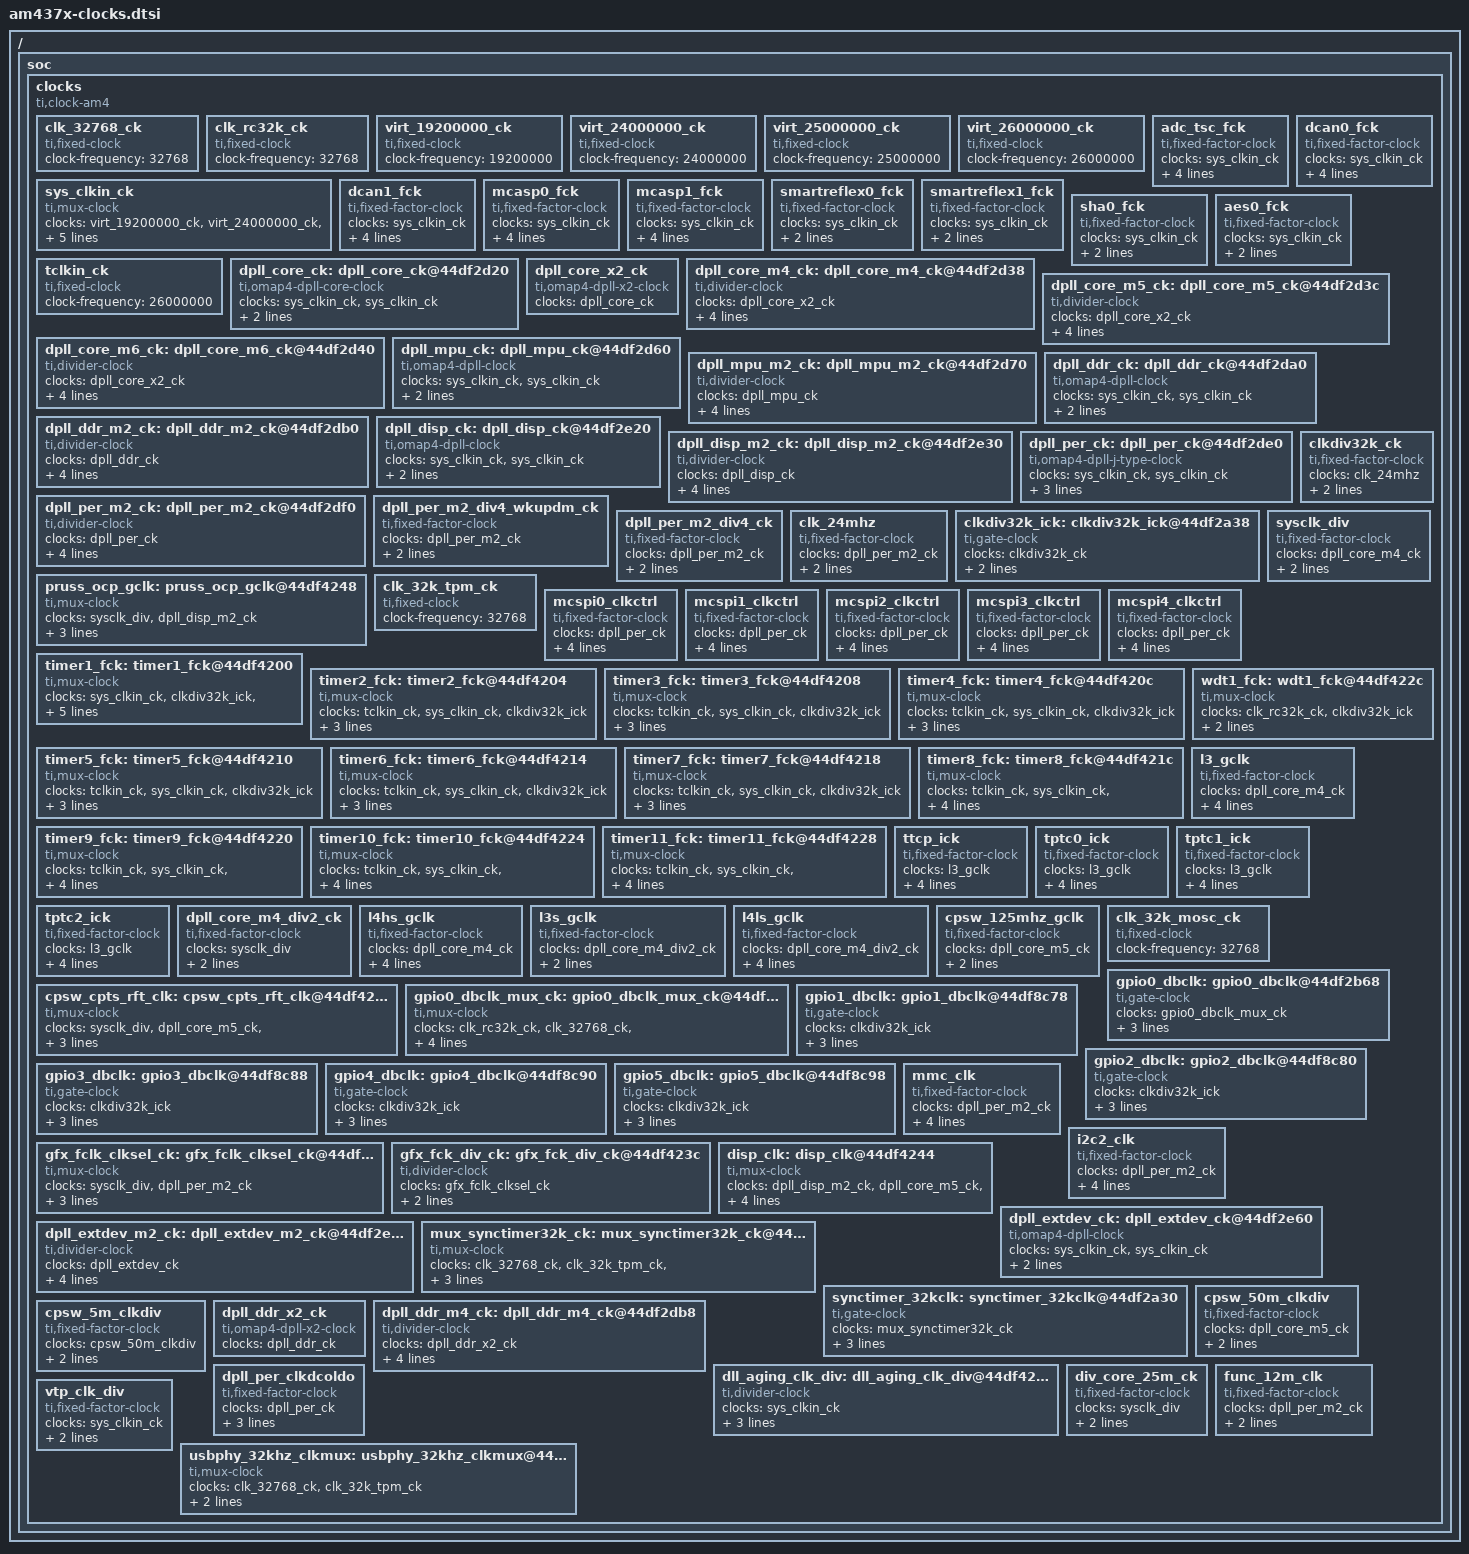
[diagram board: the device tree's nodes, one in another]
/* am437x-clocks.dtsi - TI AM4377 LBC board clock data */

/*
 * Copyright (c) 2014 Wind River Systems, Inc.
 *
 * The right to copy, distribute, modify or otherwise make use
 * of this software may be licensed only pursuant to the terms
 * of an applicable Wind River license agreement.
 */
        
/*
modification history
--------------------
02jun14,m_w  created (US40646)
*/
    
/{
 soc
    {
    clocks /* clock system */ 
        {
        compatible     = "ti,clock-am4";
        #address-cells = <1>;
        #size-cells    = <1>;
        ranges;
        
        clk_32768_ck: clk_32768_ck {
                #clock-cells    = <0>;
                compatible      = "ti,fixed-clock";
                clock-frequency = <32768>;
        };
        
        /*
         * The accuracy of this clock source is -50 to 100% making this
         * incapable of providing reliable clock alternative. Hence try
         * to avoid using this as a clock source.
         */
         
        clk_rc32k_ck: clk_rc32k_ck {
                #clock-cells    = <0>;
                compatible      = "ti,fixed-clock";
                clock-frequency = <32768>;
        };
        
        virt_19200000_ck: virt_19200000_ck {
                #clock-cells    = <0>;
                compatible      = "ti,fixed-clock";
                clock-frequency = <19200000>;
        };
        
        virt_24000000_ck: virt_24000000_ck {
                #clock-cells    = <0>;
                compatible      = "ti,fixed-clock";
                clock-frequency = <24000000>;
        };
        
        virt_25000000_ck: virt_25000000_ck {
                #clock-cells    = <0>;
                compatible      = "ti,fixed-clock";
                clock-frequency = <25000000>;
        };
        
        virt_26000000_ck: virt_26000000_ck {
                #clock-cells    = <0>;
                compatible      = "ti,fixed-clock";
                clock-frequency = <26000000>;
        };
        
        sys_clkin_ck: sys_clkin_ck {
                #clock-cells    = <0>;
                compatible      = "ti,mux-clock";
                clocks          = <&virt_19200000_ck>, <&virt_24000000_ck>, 
                                  <&virt_25000000_ck>, <&virt_26000000_ck>;
                reg             = <0x44e10040 0x4>;
                bit-shift       = <22>;
                bit-mask        = <0x3>;
                module-en-mask  = <0x3>;
                reg-names       = "clk-select";
        };

        adc_tsc_fck: adc_tsc_fck {
                #clock-cells    = <0>;
                compatible      = "ti,fixed-factor-clock";
                clocks          = <&sys_clkin_ck>;
                clock-mult      = <1>;
                clock-div       = <1>;
                reg             = <0x44df8a30 0x4>; /* PRCM_CM_PER_ADC1_CLKCTRL */
                reg-names       = "control";
                module-en-mask  = <0x3>;                 
        };

        dcan0_fck: dcan0_fck {
                #clock-cells    = <0>;
                compatible      = "ti,fixed-factor-clock";
                clocks          = <&sys_clkin_ck>;
                clock-mult      = <1>;
                clock-div       = <1>;
                reg             = <0x44df8c28 0x4>; /* PRCM_CM_PER_DCAN0_CLKCTRL */
                reg-names       = "control";
                module-en-mask  = <0x3>;                
        };

        dcan1_fck: dcan1_fck {
                #clock-cells    = <0>;
                compatible      = "ti,fixed-factor-clock";
                clocks          = <&sys_clkin_ck>;
                clock-mult      = <1>;
                clock-div       = <1>;
                reg             = <0x44df8c30 0x4>; /* PRCM_CM_PER_DCAN1_CLKCTRL */
                reg-names       = "control";
                module-en-mask  = <0x3>;                 
        };

        mcasp0_fck: mcasp0_fck {
                #clock-cells    = <0>;
                compatible      = "ti,fixed-factor-clock";
                clocks          = <&sys_clkin_ck>;
                clock-mult      = <1>;
                clock-div       = <1>;
                reg             = <0x44df8a38 0x4>; /* PRCM_CM_PER_MCASP0_CLKCTRL */
                reg-names       = "control";
                module-en-mask  = <0x3>;                
        };

        mcasp1_fck: mcasp1_fck {
                #clock-cells    = <0>;
                compatible      = "ti,fixed-factor-clock";
                clocks          = <&sys_clkin_ck>;
                clock-mult      = <1>;
                clock-div       = <1>;
                reg             = <0x44df8a40 0x4>; /* PRCM_CM_PER_MCASP1_CLKCTRL */
                reg-names       = "control";
                module-en-mask  = <0x3>;
        };

        smartreflex0_fck: smartreflex0_fck {
                #clock-cells    = <0>;
                compatible      = "ti,fixed-factor-clock";
                clocks          = <&sys_clkin_ck>;
                clock-mult      = <1>;
                clock-div       = <1>;
        };

        smartreflex1_fck: smartreflex1_fck {
                #clock-cells    = <0>;
                compatible      = "ti,fixed-factor-clock";
                clocks          = <&sys_clkin_ck>;
                clock-mult      = <1>;
                clock-div       = <1>;
        };

        sha0_fck: sha0_fck {
                #clock-cells    = <0>;
                compatible      = "ti,fixed-factor-clock";
                clocks          = <&sys_clkin_ck>;
                clock-mult      = <1>;
                clock-div       = <1>;
        };

        aes0_fck: aes0_fck {
                #clock-cells    = <0>;
                compatible      = "ti,fixed-factor-clock";
                clocks          = <&sys_clkin_ck>;
                clock-mult      = <1>;
                clock-div       = <1>;
        };

        tclkin_ck: tclkin_ck {
                #clock-cells    = <0>;
                compatible      = "ti,fixed-clock";
                clock-frequency = <26000000>;
        };
        
        dpll_core_ck: dpll_core_ck@44df2d20 {
                #clock-cells    = <0>;
                compatible      = "ti,omap4-dpll-core-clock";
                clocks          = <&sys_clkin_ck>, <&sys_clkin_ck>;
                reg             = <0x44df2d20 0x4>, 
                                  <0x44df2d24 0x4>, 
                                  <0x44df2d2c 0x4>;
                reg-names       = "control", "idlest", "mult-div1";
        };
        
        dpll_core_x2_ck: dpll_core_x2_ck {
                #clock-cells    = <0>;
                compatible      = "ti,omap4-dpll-x2-clock";
                clocks          = <&dpll_core_ck>;
        };
        
        dpll_core_m4_ck: dpll_core_m4_ck@44df2d38 {
                #clock-cells    = <0>;
                compatible      = "ti,divider-clock";
                clocks          = <&dpll_core_x2_ck>;
                reg             = <0x44df2d38 0x4>;
                reg-names       = "control";
                bit-mask        = <0x1f>;
                enable-shift    = <9>;
                index-starts-at-one;
        };
        
        dpll_core_m5_ck: dpll_core_m5_ck@44df2d3c {
                #clock-cells    = <0>;
                compatible      = "ti,divider-clock";
                clocks          = <&dpll_core_x2_ck>;
                reg             = <0x44df2d3c 0x4>;
                reg-names       = "control";
                bit-mask        = <0x1f>;
                enable-shift    = <9>;                
                index-starts-at-one;
        };
        
        dpll_core_m6_ck: dpll_core_m6_ck@44df2d40 {
                #clock-cells    = <0>;
                compatible      = "ti,divider-clock";
                clocks          = <&dpll_core_x2_ck>;
                reg             = <0x44df2d40 0x4>;
                reg-names       = "control";
                bit-mask        = <0x1f>;
                enable-shift    = <9>;
                index-starts-at-one;
        };
        
        dpll_mpu_ck: dpll_mpu_ck@44df2d60 {
                #clock-cells    = <0>;
                compatible      = "ti,omap4-dpll-clock";
                clocks          = <&sys_clkin_ck>, <&sys_clkin_ck>;
                reg             = <0x44df2d60 0x4>, 
                                  <0x44df2d64 0x4>, 
                                  <0x44df2d6c 0x4>;
                reg-names       = "control", "idlest", "mult-div1";
        };
        
        dpll_mpu_m2_ck: dpll_mpu_m2_ck@44df2d70 {
                #clock-cells    = <0>;
                compatible      = "ti,divider-clock";
                clocks          = <&dpll_mpu_ck>;
                reg             = <0x44df2d70 0x4>;
                reg-names       = "control";
                bit-mask        = <0x1f>;
                enable-shift    = <9>;                
                index-starts-at-one;
        };
        
        dpll_ddr_ck: dpll_ddr_ck@44df2da0 {
                #clock-cells    = <0>;
                compatible      = "ti,omap4-dpll-clock";
                clocks          = <&sys_clkin_ck>, <&sys_clkin_ck>;
                reg             = <0x44df2da0 0x4>,
                                  <0x44df2da4 0x4>,
                                  <0x44df2dac 0x4>;
                reg-names       = "control", "idlest", "mult-div1";
        };
        
        dpll_ddr_m2_ck: dpll_ddr_m2_ck@44df2db0 {
                #clock-cells    = <0>;
                compatible      = "ti,divider-clock";
                clocks          = <&dpll_ddr_ck>;
                reg             = <0x44df2db0 0x4>;
                reg-names       = "control";
                bit-mask        = <0x1f>;
                enable-shift    = <9>;                
                index-starts-at-one;
        };
        
        dpll_disp_ck: dpll_disp_ck@44df2e20 {
                #clock-cells    = <0>;
                compatible      = "ti,omap4-dpll-clock";
                clocks          = <&sys_clkin_ck>, <&sys_clkin_ck>;
                reg             = <0x44df2e20 0x4>,
                                  <0x44df2e24 0x4>,
                                  <0x44df2e2c 0x4>;
                reg-names = "control", "idlest", "mult-div1";
        };
        
        dpll_disp_m2_ck: dpll_disp_m2_ck@44df2e30 {
                #clock-cells    = <0>;
                compatible      = "ti,divider-clock";
                clocks          = <&dpll_disp_ck>;
                reg             = <0x44df2e30 0x4>;
                reg-names       = "control";
                bit-mask        = <0x1f>;
                enable-shift    = <9>;                
                index-starts-at-one;
        };
        
        dpll_per_ck: dpll_per_ck@44df2de0 {
                #clock-cells    = <0>;
                compatible      = "ti,omap4-dpll-j-type-clock";
                clocks          = <&sys_clkin_ck>, <&sys_clkin_ck>;
                reg             = <0x44df2de0 0x4>,
                                  <0x44df2de4 0x4>,
                                  <0x44df2dec 0x4>;
                reg-names       = "control", "idlest", "mult-div1";
                j-type          = <1>; /* 1: J-type dpll, 0: none-J-type dpll */
        };
        
        dpll_per_m2_ck: dpll_per_m2_ck@44df2df0 {
                #clock-cells    = <0>;
                compatible      = "ti,divider-clock";
                clocks          = <&dpll_per_ck>;
                reg             = <0x44df2df0 0x4>;
                reg-names       = "control";
                bit-mask        = <0x7f>;
                enable-shift    = <9>;                
                index-starts-at-one;
        };
        
        dpll_per_m2_div4_wkupdm_ck: dpll_per_m2_div4_wkupdm_ck {
                #clock-cells    = <0>;
                compatible      = "ti,fixed-factor-clock";
                clocks          = <&dpll_per_m2_ck>;
                clock-mult      = <1>;
                clock-div       = <4>;
        };
        
        dpll_per_m2_div4_ck: dpll_per_m2_div4_ck {
                #clock-cells    = <0>;
                compatible      = "ti,fixed-factor-clock";
                clocks          = <&dpll_per_m2_ck>;
                clock-mult      = <1>;
                clock-div       = <4>;
        };
                
        clk_24mhz: clk_24mhz {
                #clock-cells    = <0>;
                compatible      = "ti,fixed-factor-clock";
                clocks          = <&dpll_per_m2_ck>;
                clock-mult      = <1>;
                clock-div       = <8>;
        };
        
        clkdiv32k_ck: clkdiv32k_ck {
                #clock-cells    = <0>;
                compatible      = "ti,fixed-factor-clock";
                clocks          = <&clk_24mhz>;
                clock-mult      = <1>;
                clock-div       = <732>;
        };
        
        clkdiv32k_ick: clkdiv32k_ick@44df2a38 {
                #clock-cells    = <0>;
                compatible      = "ti,gate-clock";
                clocks          = <&clkdiv32k_ck>;
                fck-ctrl-shift  = <8>; /* there is no module-en-mask for this clock*/
                reg             = <0x44df2a38 0x4>;
                reg-names       = "control";
        };
        
        sysclk_div: sysclk_div {
                #clock-cells    = <0>;
                compatible      = "ti,fixed-factor-clock";
                clocks          = <&dpll_core_m4_ck>;
                clock-mult      = <1>;
                clock-div       = <1>;
        };
        
        pruss_ocp_gclk: pruss_ocp_gclk@44df4248 {
                #clock-cells    = <0>;
                compatible      = "ti,mux-clock";
                clocks          = <&sysclk_div>,
                				  <&dpll_disp_m2_ck>;
                reg             = <0x44df4248 0x4>,
                				  <0x44df8b20 0x4>;
                reg-names       = "clk-select",
                				  "control";
                bit-mask        = <0x1>;
                module-en-mask  = <0x2>;
        };
        
        clk_32k_tpm_ck: clk_32k_tpm_ck {
                #clock-cells    = <0>;
                compatible      = "ti,fixed-clock";
                clock-frequency = <32768>;
        };
        
		mcspi0_clkctrl: mcspi0_clkctrl {
                #clock-cells    = <0>;
                compatible      = "ti,fixed-factor-clock";
                clocks          = <&dpll_per_ck>;
                clock-mult      = <1>;
                clock-div       = <4>;
                module-en-mask  = <0x2>;
                reg             = <0x44df8D00 0x4>; /* PRCM_CM_PER_SPI0_CLKCTRL */
                reg-names       = "control";                
        };
        
		mcspi1_clkctrl: mcspi1_clkctrl {
		        #clock-cells    = <0>;
		        compatible      = "ti,fixed-factor-clock";
		        clocks          = <&dpll_per_ck>;
		        clock-mult      = <1>;
		        clock-div       = <4>;
		        module-en-mask  = <0x2>;
		        reg             = <0x44df8D08 0x4>; /* PRCM_CM_PER_SPI1_CLKCTRL */
		        reg-names       = "control";                
		        };
        
        mcspi2_clkctrl: mcspi2_clkctrl {
		        #clock-cells    = <0>;
		        compatible      = "ti,fixed-factor-clock";
		        clocks          = <&dpll_per_ck>;
		        clock-mult      = <1>;
		        clock-div       = <4>;
		        module-en-mask  = <0x2>;
		        reg             = <0x44df8D10 0x4>; /* PRCM_CM_PER_SPI2_CLKCTRL */
		        reg-names       = "control";                
		        };
        
        mcspi3_clkctrl: mcspi3_clkctrl {
		        #clock-cells    = <0>;
		        compatible      = "ti,fixed-factor-clock";
		        clocks          = <&dpll_per_ck>;
		        clock-mult      = <1>;
		        clock-div       = <4>;
		        module-en-mask  = <0x2>;
		        reg             = <0x44df8D18 0x4>; /* PRCM_CM_PER_SPI3_CLKCTRL */
		        reg-names       = "control";                
		        };
        
        mcspi4_clkctrl: mcspi4_clkctrl {
		        #clock-cells    = <0>;
		        compatible      = "ti,fixed-factor-clock";
		        clocks          = <&dpll_per_ck>;
		        clock-mult      = <1>;
		        clock-div       = <4>;
		        module-en-mask  = <0x2>;
		        reg             = <0x44df8D20 0x4>; /* PRCM_CM_PER_SPI4_CLKCTRL */
		        reg-names       = "control";                
		        };
        
        timer1_fck: timer1_fck@44df4200 {
                #clock-cells    = <0>;
                compatible      = "ti,mux-clock";
                clocks          = <&sys_clkin_ck>, <&clkdiv32k_ick>, 
                                  <&tclkin_ck>, <&clk_rc32k_ck>, 
                                  <&clk_32768_ck>, <&clk_32k_tpm_ck>;
                reg             = <0x44df4200 0x4>,
                                  <0x44df2b28 0x4>; /* PRCM_CM_WKUP_TIMER1_CLKCTRL */
                reg-names       = "clk-select", "control";
                module-en-mask  = <0x3>;
                bit-mask        = <0x7>;
        };
        
        timer2_fck: timer2_fck@44df4204 {
                #clock-cells    = <0>;
                compatible      = "ti,mux-clock";
                clocks          = <&tclkin_ck>, <&sys_clkin_ck>, <&clkdiv32k_ick>;
                reg             = <0x44df4204 0x4>, <0x44df8d30 0x4>;
                reg-names       = "clk-select", "control";
                module-en-mask  = <0x3>;
                bit-mask        = <0x3>;
        };
        
        timer3_fck: timer3_fck@44df4208 {
                #clock-cells    = <0>;
                compatible      = "ti,mux-clock";
                clocks          = <&tclkin_ck>, <&sys_clkin_ck>, <&clkdiv32k_ick>;
                reg             = <0x44df4208 0x4>, <0x44df8d38 0x4>;
                reg-names       = "clk-select", "control";
                module-en-mask  = <0x3>;
                bit-mask        = <0x3>;
        };
        
        timer4_fck: timer4_fck@44df420c {
                #clock-cells    = <0>;
                compatible      = "ti,mux-clock";
                clocks          = <&tclkin_ck>, <&sys_clkin_ck>, <&clkdiv32k_ick>;
                reg             = <0x44df420c 0x4>, <0x44df8d40 0x4>;
                reg-names       = "clk-select", "control";
                module-en-mask  = <0x3>;
                bit-mask        = <0x3>;
        };
        
        timer5_fck: timer5_fck@44df4210 {
                #clock-cells    = <0>;
                compatible      = "ti,mux-clock";
                clocks          = <&tclkin_ck>, <&sys_clkin_ck>, <&clkdiv32k_ick>;
                reg             = <0x44df4210 0x4>, <0x44df8d48 0x4>;
                reg-names       = "clk-select", "control";
                module-en-mask  = <0x3>;
                bit-mask        = <0x3>;
        };
        
        timer6_fck: timer6_fck@44df4214 {
                #clock-cells    = <0>;
                compatible      = "ti,mux-clock";
                clocks          = <&tclkin_ck>, <&sys_clkin_ck>, <&clkdiv32k_ick>;
                reg             = <0x44df4214 0x4>, <0x44df8d50 0x4>;
                reg-names       = "clk-select", "control";
                module-en-mask  = <0x3>;
                bit-mask        = <0x3>;
        };
        
        timer7_fck: timer7_fck@44df4218 {
                #clock-cells    = <0>;
                compatible      = "ti,mux-clock";
                clocks          = <&tclkin_ck>, <&sys_clkin_ck>, <&clkdiv32k_ick>;
                reg             = <0x44df4218 0x4>, <0x44df8d58 0x4>;
                reg-names       = "clk-select", "control";
                module-en-mask  = <0x3>;
                bit-mask        = <0x3>;
        };

        timer8_fck: timer8_fck@44df421c {
                #clock-cells    = <0>;
                compatible      = "ti,mux-clock";
                clocks          = <&tclkin_ck>, <&sys_clkin_ck>, 
                                  <&clkdiv32k_ick>, <&clk_32k_tpm_ck>;
                reg             = <0x44df421c 0x4>, <0x44df8d60 0x4>;
                reg-names       = "clk-select", "control";
                module-en-mask  = <0x3>;
                bit-mask        = <0x3>;
        };
        
        timer9_fck: timer9_fck@44df4220 {
                #clock-cells    = <0>;
                compatible      = "ti,mux-clock";
                clocks          = <&tclkin_ck>, <&sys_clkin_ck>, 
                                  <&clkdiv32k_ick>, <&clk_32k_tpm_ck>;
                reg             = <0x44df4220 0x4>, <0x44df8d68 0x4>;
                reg-names       = "clk-select", "control";
                module-en-mask  = <0x3>;
                bit-mask        = <0x3>;
        };
        
        timer10_fck: timer10_fck@44df4224 {
                #clock-cells    = <0>;
                compatible      = "ti,mux-clock";
                clocks          = <&tclkin_ck>, <&sys_clkin_ck>, 
                                  <&clkdiv32k_ick>, <&clk_32k_tpm_ck>;
                reg             = <0x44df4224 0x4>, <0x44df8d70 0x4>;
                reg-names       = "clk-select", "control";
                module-en-mask  = <0x3>;
                bit-mask        = <0x3>;
        };
        
        timer11_fck: timer11_fck@44df4228 {
                #clock-cells    = <0>;
                compatible      = "ti,mux-clock";
                clocks          = <&tclkin_ck>, <&sys_clkin_ck>,
                                  <&clkdiv32k_ick>, <&clk_32k_tpm_ck>;
                reg             = <0x44df4228 0x4>, <0x44df8d78 0x4>;
                reg-names       = "clk-select", "control";
                module-en-mask  = <0x3>;
                bit-mask        = <0x3>;
        };
        
        wdt1_fck: wdt1_fck@44df422c {
                #clock-cells    = <0>;
                compatible      = "ti,mux-clock";
                clocks          = <&clk_rc32k_ck>, <&clkdiv32k_ick>;
                reg             = <0x44df422c 0x4>;
                reg-names       = "clk-select";
                bit-mask        = <0x1>;
        };
        
        l3_gclk: l3_gclk {
                #clock-cells    = <0>;
                compatible      = "ti,fixed-factor-clock";
                clocks          = <&dpll_core_m4_ck>;
                clock-mult      = <1>;
                clock-div       = <1>;
                reg             = <0x44df8820 0x4>; /* PRCM_CM_PER_L3_CLKCTRL */
                reg-names       = "control";
                module-en-mask  = <0x3>;                 
        };

        ttcp_ick: ttcp_ick {
                #clock-cells    = <0>;
                compatible      = "ti,fixed-factor-clock";
                clocks          = <&l3_gclk>;
                clock-mult      = <1>;
                clock-div       = <1>;
                reg             = <0x44df8878 0x4>; /* PRCM_CM_PER_TPCC_CLKCTRL */
                reg-names       = "control";
                module-en-mask  = <0x3>;                
        };

        tptc0_ick: tptc0_ick {
                #clock-cells    = <0>;
                compatible      = "ti,fixed-factor-clock";
                clocks          = <&l3_gclk>;
                clock-mult      = <1>;
                clock-div       = <1>;
                reg             = <0x44df8880 0x4>; /* PRCM_CM_PER_TPTC0_CLKCTRL */
                reg-names       = "control";
                module-en-mask  = <0x3>;                
        };

        tptc1_ick: tptc1_ick {
                #clock-cells    = <0>;
                compatible      = "ti,fixed-factor-clock";
                clocks          = <&l3_gclk>;
                clock-mult      = <1>;
                clock-div       = <1>;
                reg             = <0x44df8888 0x4>; /* PRCM_CM_PER_TPTC1_CLKCTRL */
                reg-names       = "control";
                module-en-mask  = <0x3>;                
        }; 

        tptc2_ick: tptc2_ick {
                #clock-cells    = <0>;
                compatible      = "ti,fixed-factor-clock";
                clocks          = <&l3_gclk>;
                clock-mult      = <1>;
                clock-div       = <1>;
                reg             = <0x44df8890 0x4>; /* PRCM_CM_PER_TPTC2_CLKCTRL */
                reg-names       = "control";
                module-en-mask  = <0x3>;                 
        };         
        
        dpll_core_m4_div2_ck: dpll_core_m4_div2_ck {
                #clock-cells    = <0>;
                compatible      = "ti,fixed-factor-clock";
                clocks          = <&sysclk_div>;
                clock-mult      = <1>;
                clock-div       = <2>;
        };
        
        l4hs_gclk: l4hs_gclk {
                #clock-cells    = <0>;
                compatible      = "ti,fixed-factor-clock";
                clocks          = <&dpll_core_m4_ck>;
                clock-mult      = <1>;
                clock-div       = <1>;
                reg             = <0x44df88a0 0x4>; /* PRCM_CM_PER_L4HS_CLKCTRL */
                reg-names       = "control";
                module-en-mask  = <0x3>;                
        };
        
        l3s_gclk: l3s_gclk {
                #clock-cells    = <0>;
                compatible      = "ti,fixed-factor-clock";
                clocks          = <&dpll_core_m4_div2_ck>;
                clock-mult      = <1>;
                clock-div       = <1>;
        };
        
        l4ls_gclk: l4ls_gclk {
                #clock-cells    = <0>;
                compatible      = "ti,fixed-factor-clock";
                clocks          = <&dpll_core_m4_div2_ck>;
                clock-mult      = <1>;
                clock-div       = <1>;
                reg             = <0x44df8c20 0x4>; /* PRCM_CM_PER_L4LS_CLKCTRL */
                reg-names       = "control";
                module-en-mask  = <0x3>;                    
        };
        
        cpsw_125mhz_gclk: cpsw_125mhz_gclk {
                #clock-cells    = <0>;
                compatible      = "ti,fixed-factor-clock";
                clocks          = <&dpll_core_m5_ck>;
                clock-mult      = <1>;
                clock-div       = <2>;
        };
        
        cpsw_cpts_rft_clk: cpsw_cpts_rft_clk@44df4238 {
                #clock-cells    = <0>;
                compatible      = "ti,mux-clock";
                clocks          = <&sysclk_div>, <&dpll_core_m5_ck>, <&dpll_disp_m2_ck>;
                reg             = <0x44df4238 0x4>;
                reg-names       = "clk-select";
                bit-mask        = <0x3>;
        };
        
        clk_32k_mosc_ck: clk_32k_mosc_ck {
                #clock-cells    = <0>;
                compatible      = "ti,fixed-clock";
                clock-frequency = <32768>;
        };
        
        gpio0_dbclk_mux_ck: gpio0_dbclk_mux_ck@44df4240 {
                #clock-cells    = <0>;
                compatible      = "ti,mux-clock";
                clocks          = <&clk_rc32k_ck>, <&clk_32768_ck>, <&clkdiv32k_ick>, <&clk_32k_mosc_ck>, <&clk_32k_tpm_ck>;
                reg             = <0x44df4240 0x4>;
                reg-names       = "clk-select";
                bit-mask        = <0x7>;
        };
        
        gpio0_dbclk: gpio0_dbclk@44df2b68 {
                #clock-cells    = <0>;
                compatible      = "ti,gate-clock";
                clocks          = <&gpio0_dbclk_mux_ck>;
                fck-ctrl-shift  = <8>;
                module-en-mask  = <0x3>;
                reg             = <0x44df2b68 0x4>;
                reg-names       = "control";
        };
        
        gpio1_dbclk: gpio1_dbclk@44df8c78 {
                #clock-cells    = <0>;
                compatible      = "ti,gate-clock";
                clocks          = <&clkdiv32k_ick>;
                fck-ctrl-shift  = <8>;
                module-en-mask  = <0x3>;
                reg             = <0x44df8c78 0x4>;
                reg-names       = "control";
        };
        
        gpio2_dbclk: gpio2_dbclk@44df8c80 {
                #clock-cells    = <0>;
                compatible      = "ti,gate-clock";
                clocks          = <&clkdiv32k_ick>;
                fck-ctrl-shift  = <8>;
                module-en-mask  = <0x3>;
                reg             = <0x44df8c80 0x4>;
                reg-names       = "control";
        };
        
        gpio3_dbclk: gpio3_dbclk@44df8c88 {
                #clock-cells    = <0>;
                compatible      = "ti,gate-clock";
                clocks          = <&clkdiv32k_ick>;
                fck-ctrl-shift  = <8>;
                module-en-mask  = <0x3>;
                reg             = <0x44df8c88 0x4>;
                reg-names       = "control";
        };
        
        gpio4_dbclk: gpio4_dbclk@44df8c90 {
                #clock-cells    = <0>;
                compatible      = "ti,gate-clock";
                clocks          = <&clkdiv32k_ick>;
                fck-ctrl-shift  = <8>;
                module-en-mask  = <0x3>;
                reg             = <0x44df8c90 0x4>;
                reg-names       = "control";
        };
        
        gpio5_dbclk: gpio5_dbclk@44df8c98 {
                #clock-cells    = <0>;
                compatible      = "ti,gate-clock";
                clocks          = <&clkdiv32k_ick>;
                fck-ctrl-shift  = <8>;
                module-en-mask  = <0x3>;
                reg             = <0x44df8c98 0x4>;
                reg-names       = "control";
        };
        
        mmc_clk: mmc_clk {
                #clock-cells    = <0>;
                compatible      = "ti,fixed-factor-clock";
                clocks          = <&dpll_per_m2_ck>;
                clock-mult      = <1>;
                clock-div       = <2>;
                module-en-mask  = <0x3>;
                reg             = <0x44df8cc0 0x4>; /* PRCM_CM_PER_MMC0_CLKCTRL */
                reg-names       = "control";                
        };
		
		i2c2_clk:i2c2_clk {
				#clock-cells    = <0>;
                compatible      = "ti,fixed-factor-clock";
                clocks          = <&dpll_per_m2_ck>;
				clock-mult      = <1>;
                clock-div       = <4>;
				module-en-mask  = <0x3>;
                reg             = <0x44df8cb0 0x4>; /* PRCM_CM_PER_I2C2_CLKCTRL */
                reg-names       = "control";
		};
        
        gfx_fclk_clksel_ck: gfx_fclk_clksel_ck@44df423c {
                #clock-cells    = <0>;
                compatible      = "ti,mux-clock";
                clocks          = <&sysclk_div>, <&dpll_per_m2_ck>;
                bit-shift       = <1>;
                reg             = <0x44df423c 0x4>;
                reg-names       = "clk-select";
                bit-mask        = <0x1>;
        };
        
        gfx_fck_div_ck: gfx_fck_div_ck@44df423c {
                #clock-cells    = <0>;
                compatible      = "ti,divider-clock";
                clocks          = <&gfx_fclk_clksel_ck>;
                reg             = <0x44df423c 0x4>;
                reg-names       = "control";
                bit-mask        = <0x1>;
        };
        
        disp_clk: disp_clk@44df4244 {
                #clock-cells    = <0>;
                compatible      = "ti,mux-clock";
                clocks          = <&dpll_disp_m2_ck>, <&dpll_core_m5_ck>,
                                  <&dpll_per_m2_ck>;
                reg             = <0x44df4244 0x4>;
                reg-names       = "clk-select";
                bit-mask        = <0x3>;
                set-rate-parent;
        };
        
        dpll_extdev_ck: dpll_extdev_ck@44df2e60 {
                #clock-cells    = <0>;
                compatible      = "ti,omap4-dpll-clock";
                clocks          = <&sys_clkin_ck>, <&sys_clkin_ck>;
                reg             = <0x44df2e60 0x4>, <0x44df2e64 0x4>, <0x44df2e6c 0x4>;
                reg-names       = "control", "idlest", "mult-div1";
        };
        
        dpll_extdev_m2_ck: dpll_extdev_m2_ck@44df2e70 {
                #clock-cells    = <0>;
                compatible      = "ti,divider-clock";
                clocks          = <&dpll_extdev_ck>;
                reg             = <0x44df2e70 0x4>;
                reg-names       = "control";
                bit-mask        = <0x7f>;
                enable-shift    = <9>;                
                index-starts-at-one;
        };
        
        mux_synctimer32k_ck: mux_synctimer32k_ck@44df4230 {
                #clock-cells    = <0>;
                compatible      = "ti,mux-clock";
                clocks          = <&clk_32768_ck>, <&clk_32k_tpm_ck>, <&clkdiv32k_ick>;
                reg             = <0x44df4230 0x4>;
                reg-names       = "clk-select";
                bit-mask        = <0x3>;
        };
        
        synctimer_32kclk: synctimer_32kclk@44df2a30 {
                #clock-cells    = <0>;
                compatible      = "ti,gate-clock";
                clocks          = <&mux_synctimer32k_ck>;
                fck-ctrl-shift  = <8>;
                module-en-mask  = <0x3>;
                reg             = <0x44df2a30 0x4>;
                reg-names       = "control";
        };
                
        cpsw_50m_clkdiv: cpsw_50m_clkdiv {
                #clock-cells    = <0>;
                compatible      = "ti,fixed-factor-clock";
                clocks          = <&dpll_core_m5_ck>;
                clock-mult      = <1>;
                clock-div       = <1>;
        };
        
        cpsw_5m_clkdiv: cpsw_5m_clkdiv {
                #clock-cells    = <0>;
                compatible      = "ti,fixed-factor-clock";
                clocks          = <&cpsw_50m_clkdiv>;
                clock-mult      = <1>;
                clock-div       = <10>;
        };
        
        dpll_ddr_x2_ck: dpll_ddr_x2_ck {
                #clock-cells    = <0>;
                compatible      = "ti,omap4-dpll-x2-clock";
                clocks          = <&dpll_ddr_ck>;
        };
        
        dpll_ddr_m4_ck: dpll_ddr_m4_ck@44df2db8 {
                #clock-cells    = <0>;
                compatible      = "ti,divider-clock";
                clocks          = <&dpll_ddr_x2_ck>;
                reg             = <0x44df2db8 0x4>;
                reg-names       = "control";
                bit-mask        = <0x1f>;
                enable-shift    = <9>;                
                index-starts-at-one;
        };
        
        dpll_per_clkdcoldo: dpll_per_clkdcoldo {
                #clock-cells    = <0>;
                compatible      = "ti,fixed-factor-clock";
                clocks          = <&dpll_per_ck>;
                reg             = <0x44df2e14 0x4>;
                clock-mult      = <1>;
                clock-div       = <1>;
        };
        
        dll_aging_clk_div: dll_aging_clk_div@44df4250 {
                #clock-cells    = <0>;
                compatible      = "ti,divider-clock";
                clocks          = <&sys_clkin_ck>;
                reg             = <0x44df4250 0x4>;
                reg-names       = "control";
                table           = < 8  0 >, /* 0h (R/W) = Divide by 8 */
                                  < 16 1 >, /* 1h (R/W) = Divide by 16 */
                                  < 32 2 >; /* 2h (R/W) = Divide by 32 */
                bit-mask        = <0x3>;
        };
        
        div_core_25m_ck: div_core_25m_ck {
                #clock-cells    = <0>;
                compatible      = "ti,fixed-factor-clock";
                clocks          = <&sysclk_div>;
                clock-mult      = <1>;
                clock-div       = <8>;
        };
        
        func_12m_clk: func_12m_clk {
                #clock-cells    = <0>;
                compatible      = "ti,fixed-factor-clock";
                clocks          = <&dpll_per_m2_ck>;
                clock-mult      = <1>;
                clock-div       = <16>;
        };
        
        vtp_clk_div: vtp_clk_div {
                #clock-cells    = <0>;
                compatible      = "ti,fixed-factor-clock";
                clocks          = <&sys_clkin_ck>;
                clock-mult      = <1>;
                clock-div       = <2>;
        };
        
        usbphy_32khz_clkmux: usbphy_32khz_clkmux@44df4260 {
                #clock-cells    = <0>;
                compatible      = "ti,mux-clock";
                clocks          = <&clk_32768_ck>, <&clk_32k_tpm_ck>;
                reg             = <0x44df4260 0x4>;
                reg-names       = "clk-select";
                bit-mask        = <0x1>;
        }; 
    };/* end of clock */
    };/* end of soc */
};/* end of root */
